# STM32U375xx register map
File version: 1.0
Registers are 32-bit, read-write, reset 0x0 unless marked. A register's access mark holds for its fields unless they carry their own. Offsets are from the block's base; [hi:lo] are bit positions; {n}, {i} and the like mark numbered series.

## USB_DRD_FS — Universal Serial Bus Full Speed Dual Role Device
Base 0x40016000
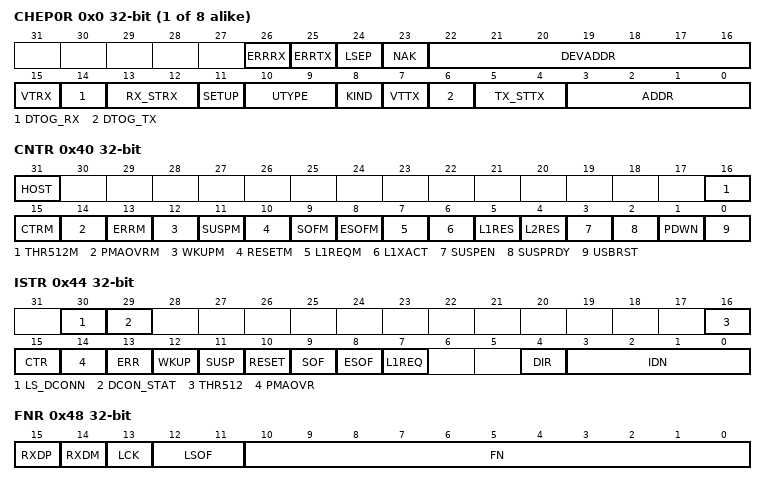
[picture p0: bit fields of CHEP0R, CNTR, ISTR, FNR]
{0x0+4i} CHEP{i}R (i=0..7) — USB Channel/Endpoint {i} register
  [26] ERRRX — Receive error
  [25] ERRTX — Transmit error
  [24] LSEP — Low Speed Endpoint (host with Hub Only)
  [23] NAK — Previous NAK detected
  [22:16] DEVADDR
  [15] VTRX — USB valid transaction received Mask
  [14] DTOG_RX — Data Toggle, for reception transfers Mask
  [13:12] RX_STRX — Status bits, for reception transfers Mask
  [11] SETUP — Setup transaction completed Mask
  [10:9] UTYPE — USB type of transaction Mask
  [8] KIND — EndPoint KIND Mask
  [7] VTTX — Valid USB transaction transmitted Mask
  [6] DTOG_TX — Data Toggle, for transmission transfers Mask
  [5:4] TX_STTX — Status bits, for transmission transfers Mask
  [3:0] ADDR — Endpoint address Mask
0x40 CNTR — Control register
  [31] HOST — Host Mode
  [16] THR512M — 512byte Threshold interrupt mask
  [15] CTRM — Correct Transfer Mask
  [14] PMAOVRM — DMA OVeR/underrun Mask
  [13] ERRM — ERRor Mask
  [12] WKUPM — WaKe UP Mask
  [11] SUSPM — SUSPend Mask
  [10] RESETM — RESET Mask
  [9] SOFM — Start Of Frame Mask
  [8] ESOFM — Expected Start Of Frame Mask
  [7] L1REQM — LPM L1 state request interrupt Mask
  [6] L1XACT — Host LPM L1 transaction request Mask
  [5] L1RES — LPM L1 Resume request/ Remote Wakeup Mask
  [4] L2RES — L2 Remote Wakeup / Resume driver Mask
  [3] SUSPEN — Suspend state enable Mask
  [2] SUSPRDY — Suspend state effective Mask
  [1] PDWN — Power DoWN Mask
  [0] USBRST — USB Reset Mask
0x44 ISTR — Interrupt status register
  [30] LS_DCONN — LS_DCONN Mask
  [29] DCON_STAT — Device Connection status (connected/Disconnected) don't cause an interrupt
  [16] THR512 — 512byte threshold interrupt (used with isochrnous single buffer )
  [15] CTR — Correct TRansfer (clear-only bit) Mask
  [14] PMAOVR — PMA OVeR/underrun (clear-only bit) Mask
  [13] ERR — ERRor (clear-only bit) Mask
  [12] WKUP — WaKe UP (clear-only bit) Mask
  [11] SUSP — SUSPend (clear-only bit) Mask
  [10] RESET — RESET Mask
  [9] SOF — Start Of Frame (clear-only bit) Mask
  [8] ESOF — Expected Start Of Frame (clear-only bit) Mask
  [7] L1REQ — LPM L1 state request Mask
  [4] DIR — DIRection of transaction (read-only bit) Mask
  [3:0] IDN — EndPoint IDentifier (read-only bit) Mask
0x48 FNR — Frame number register
  [15] RXDP — status of D+ data line Mask
  [14] RXDM — status of D- data line Mask
  [13] LCK — LoCKed Mask
  [12:11] LSOF — Lost SOF Mask
  [10:0] FN — Frame Number Mask
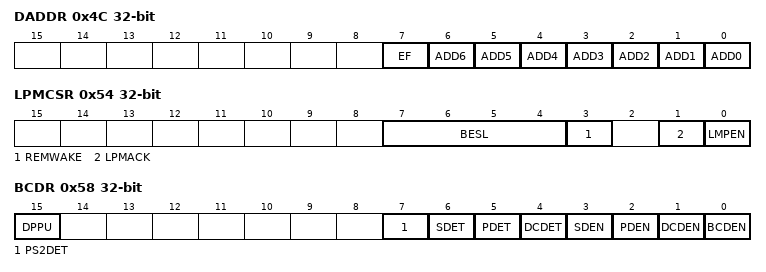
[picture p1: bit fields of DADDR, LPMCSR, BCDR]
0x4C DADDR — Device address register
  [7] EF — Enable Function Mask
  [n] ADD{n} (n=0..6) — Bit {n} Mask
0x54 LPMCSR — LPM Control and Status register
  [7:4] BESL — BESL value received with last ACKed LPM Token Mask
  [3] REMWAKE — bRemoteWake value received with last ACKed LPM Token Mask
  [1] LPMACK — LPM Token acknowledge enable Mask
  [0] LMPEN — LPM support enable Mask
0x58 BCDR — Battery Charging detector register
  [15] DPPU — DP Pull-up Enable Mask
  [7] PS2DET — PS2 port or proprietary charger detected Mask
  [6] SDET — Secondary detection (SD) status Mask
  [5] PDET — Primary detection (PD) status Mask
  [4] DCDET — Data contact detection (DCD) status Mask
  [3] SDEN — Secondary detection (SD) mode enable Mask
  [2] PDEN — Primary detection (PD) mode enable Mask
  [1] DCDEN — Data contact detection (DCD) mode enable Mask
  [0] BCDEN — Battery charging detector (BCD) enable Mask

## USB_DRD_PMA_BUFF — Universal Serial Bus PacketMemoryArea Buffer Descriptor Table
Base 0x40016400
0x00 TXBD — Transmission buffer address
0x04 RXBD — Reception buffer address

## CRC — CRC calculation unit
Base 0x40023000
0x00 DR — CRC Data register
  [31:0] DR — Data register bits
0x04 IDR — CRC Independent data register
  [31:0] IDR — General-purpose 32-bits data register bits
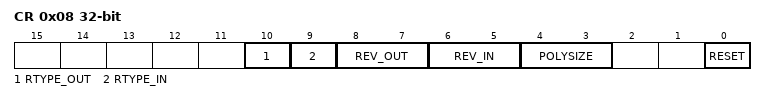
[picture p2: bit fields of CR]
0x08 CR — CRC Control register
  [10] RTYPE_OUT — RTYPE_OUT Reverse Type Output bit
    0=BIT (Output Data reverse type at bit level granularity); 1=BYTE_HALFWORD (Output Data reverse type at byte or half-word level granularity)
  [9] RTYPE_IN — RTYPE_IN Reverse Type Input bit
    0=BIT (Input Data reverse type at bit level granularity); 1=BYTE_HALFWORD (Input Data reverse type at byte or half-word level granularity)
  [8:7] REV_OUT — REV_OUT Reverse Output Data bits
  [6:5] REV_IN — REV_IN Reverse Input Data bits
  [4:3] POLYSIZE — Polynomial size bits
    0=POLYLENGTH_32B (32 bits Polynomial size); 1=POLYLENGTH_16B (16 bits Polynomial size); 2=POLYLENGTH_8B (8 bits Polynomial size); 3=POLYLENGTH_7B (7 bits Polynomial size)
  [0] RESET — RESET the CRC computation unit bit
0x10 INIT — Initial CRC value register
  [31:0] INIT — Initial CRC value bits
0x14 POL — CRC polynomial register
  [31:0] POL — Coefficients of the polynomial
